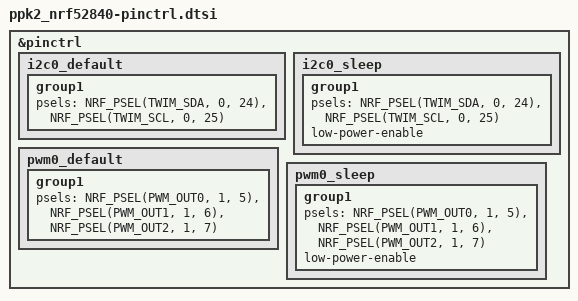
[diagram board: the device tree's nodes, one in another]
/*
 * SPDX-License-Identifier: Apache-2.0
 */

&pinctrl {
	/* U7 (24CW160 EEPROM) and U10 (MCP4451 quad digital potentiometer)
	 * share this bus.
	 */
	i2c0_default: i2c0_default {
		group1 {
			psels = <NRF_PSEL(TWIM_SDA, 0, 24)>,
				<NRF_PSEL(TWIM_SCL, 0, 25)>;
		};
	};

	i2c0_sleep: i2c0_sleep {
		group1 {
			psels = <NRF_PSEL(TWIM_SDA, 0, 24)>,
				<NRF_PSEL(TWIM_SCL, 0, 25)>;
			low-power-enable;
		};
	};

	/* Status LED channels, through the Q15/Q1 low-side MOSFETs. */
	pwm0_default: pwm0_default {
		group1 {
			psels = <NRF_PSEL(PWM_OUT0, 1, 5)>,
				<NRF_PSEL(PWM_OUT1, 1, 6)>,
				<NRF_PSEL(PWM_OUT2, 1, 7)>;
		};
	};

	pwm0_sleep: pwm0_sleep {
		group1 {
			psels = <NRF_PSEL(PWM_OUT0, 1, 5)>,
				<NRF_PSEL(PWM_OUT1, 1, 6)>,
				<NRF_PSEL(PWM_OUT2, 1, 7)>;
			low-power-enable;
		};
	};
};
